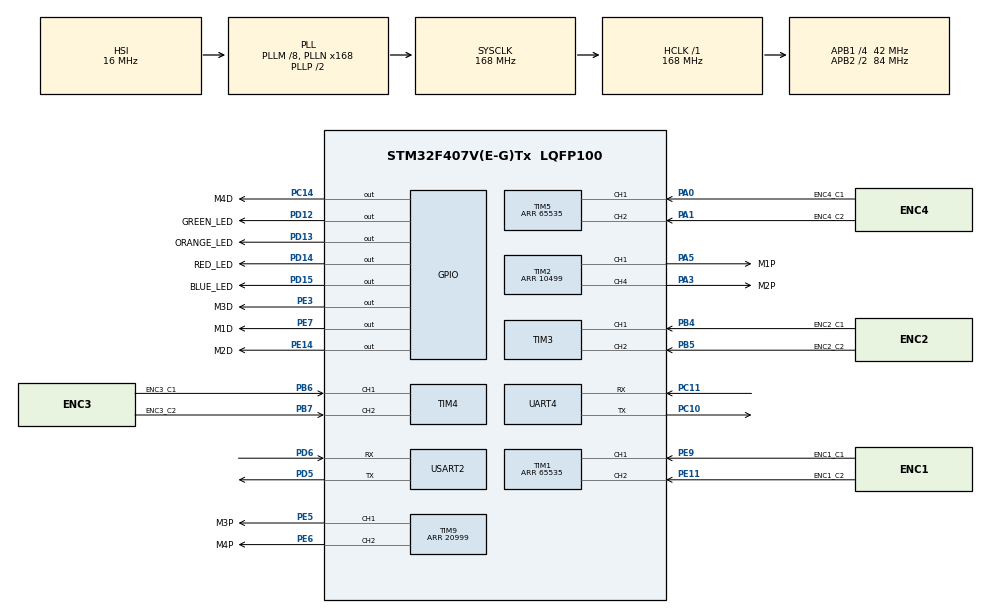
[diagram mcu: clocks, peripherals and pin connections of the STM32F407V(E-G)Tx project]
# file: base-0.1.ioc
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Dma.Request0=USART2_RX
Dma.Request1=UART4_RX
Dma.Request2=UART4_TX
Dma.UART4_RX.1.Direction=DMA_PERIPH_TO_MEMORY
Dma.UART4_RX.1.FIFOMode=DMA_FIFOMODE_DISABLE
Dma.UART4_RX.1.Instance=DMA1_Stream2
Dma.UART4_RX.1.MemDataAlignment=DMA_MDATAALIGN_BYTE
Dma.UART4_RX.1.MemInc=DMA_MINC_ENABLE
Dma.UART4_RX.1.Mode=DMA_NORMAL
Dma.UART4_RX.1.PeriphDataAlignment=DMA_PDATAALIGN_BYTE
Dma.UART4_RX.1.PeriphInc=DMA_PINC_DISABLE
Dma.UART4_RX.1.Priority=DMA_PRIORITY_LOW
Dma.UART4_TX.2.Direction=DMA_MEMORY_TO_PERIPH
Dma.UART4_TX.2.FIFOMode=DMA_FIFOMODE_DISABLE
Dma.UART4_TX.2.Instance=DMA1_Stream4
Dma.UART4_TX.2.MemDataAlignment=DMA_MDATAALIGN_BYTE
Dma.UART4_TX.2.MemInc=DMA_MINC_ENABLE
Dma.UART4_TX.2.Mode=DMA_NORMAL
Dma.UART4_TX.2.PeriphDataAlignment=DMA_PDATAALIGN_BYTE
Dma.UART4_TX.2.PeriphInc=DMA_PINC_DISABLE
Dma.UART4_TX.2.Priority=DMA_PRIORITY_LOW
Dma.USART2_RX.0.Direction=DMA_PERIPH_TO_MEMORY
Dma.USART2_RX.0.FIFOMode=DMA_FIFOMODE_DISABLE
Dma.USART2_RX.0.Instance=DMA1_Stream5
Dma.USART2_RX.0.MemDataAlignment=DMA_MDATAALIGN_BYTE
Dma.USART2_RX.0.MemInc=DMA_MINC_ENABLE
Dma.USART2_RX.0.Mode=DMA_NORMAL
Dma.USART2_RX.0.PeriphDataAlignment=DMA_PDATAALIGN_BYTE
Dma.USART2_RX.0.PeriphInc=DMA_PINC_DISABLE
Dma.USART2_RX.0.Priority=DMA_PRIORITY_MEDIUM
Mcu.Family=STM32F4
Mcu.Name=STM32F407V(E-G)Tx
Mcu.Package=LQFP100
NVIC.DMA1_Stream2_IRQn=true\:0\:0\:false\:false\:true\:false\:true\:true
NVIC.DMA1_Stream4_IRQn=true\:0\:0\:false\:false\:true\:false\:true\:true
NVIC.DMA1_Stream5_IRQn=true\:0\:0\:false\:false\:true\:false\:true\:true
NVIC.PriorityGroup=NVIC_PRIORITYGROUP_0
NVIC.USART2_IRQn=true\:0\:0\:false\:false\:true\:true\:true\:true
PA0-WKUP.GPIO_Label=ENC4_C1
PA0-WKUP.Signal=S_TIM5_CH1
PA1.GPIO_Label=ENC4_C2
PA1.Signal=S_TIM5_CH2
PA13.Mode=Serial_Wire
PA13.Signal=SYS_JTMS-SWDIO
PA14.Mode=Serial_Wire
PA14.Signal=SYS_JTCK-SWCLK
PA3.GPIO_Label=M2P
PA3.Signal=S_TIM2_CH4
PA5.GPIO_Label=M1P
PA5.Signal=S_TIM2_CH1_ETR
PB4.GPIO_Label=ENC2_C1
PB4.Signal=S_TIM3_CH1
PB5.GPIO_Label=ENC2_C2
PB5.Signal=S_TIM3_CH2
PB6.GPIO_Label=ENC3_C1
PB6.Signal=S_TIM4_CH1
PB7.GPIO_Label=ENC3_C2
PB7.Signal=S_TIM4_CH2
PC10.Mode=Asynchronous
PC10.Signal=UART4_TX
PC11.Mode=Asynchronous
PC11.Signal=UART4_RX
PC14-OSC32_IN.GPIO_Label=M4D
PC14-OSC32_IN.Signal=GPIO_Output
PD12.GPIO_Label=GREEN_LED
PD12.Signal=GPIO_Output
PD13.GPIO_Label=ORANGE_LED
PD13.Signal=GPIO_Output
PD14.GPIO_Label=RED_LED
PD14.Signal=GPIO_Output
PD15.GPIO_Label=BLUE_LED
PD15.Signal=GPIO_Output
PD5.Mode=Asynchronous
PD5.Signal=USART2_TX
PD6.Mode=Asynchronous
PD6.Signal=USART2_RX
PE11.GPIO_Label=ENC1_C2
PE11.Signal=S_TIM1_CH2
PE14.GPIO_Label=M2D
PE14.Signal=GPIO_Output
PE3.GPIO_Label=M3D
PE3.Signal=GPIO_Output
PE5.GPIO_Label=M3P
PE5.Signal=S_TIM9_CH1
PE6.GPIO_Label=M4P
PE6.Signal=S_TIM9_CH2
PE7.GPIO_Label=M1D
PE7.Signal=GPIO_Output
PE9.GPIO_Label=ENC1_C1
PE9.Signal=S_TIM1_CH1
PH0-OSC_IN.Mode=HSE-External-Oscillator
PH0-OSC_IN.Signal=RCC_OSC_IN
PH1-OSC_OUT.Mode=HSE-External-Oscillator
PH1-OSC_OUT.Signal=RCC_OSC_OUT
ProjectManager.HeapSize=0x200
ProjectManager.StackSize=0x400
ProjectManager.TargetToolchain=Makefile
RCC.48MHZClocksFreq_Value=48000000
RCC.AHBFreq_Value=168000000
RCC.APB1CLKDivider=RCC_HCLK_DIV4
RCC.APB1Freq_Value=42000000
RCC.APB1TimFreq_Value=84000000
RCC.APB2CLKDivider=RCC_HCLK_DIV2
RCC.APB2Freq_Value=84000000
RCC.APB2TimFreq_Value=168000000
RCC.CortexFreq_Value=168000000
RCC.HCLKFreq_Value=168000000
RCC.HSE_VALUE=8000000
RCC.HSI_VALUE=16000000
RCC.LSE_VALUE=32768
RCC.PLLM=8
RCC.PLLN=168
RCC.PLLQ=7
RCC.SYSCLKFreq_VALUE=168000000
RCC.SYSCLKSource=RCC_SYSCLKSOURCE_PLLCLK
RCC.VCOOutputFreq_Value=336000000
SH.S_TIM1_CH1.0=TIM1_CH1,Encoder_Interface
SH.S_TIM1_CH2.0=TIM1_CH2,Encoder_Interface
SH.S_TIM2_CH1_ETR.0=TIM2_CH1,PWM Generation1 CH1
SH.S_TIM2_CH4.0=TIM2_CH4,PWM Generation4 CH4
SH.S_TIM3_CH1.0=TIM3_CH1,Encoder_Interface
SH.S_TIM3_CH2.0=TIM3_CH2,Encoder_Interface
SH.S_TIM4_CH1.0=TIM4_CH1,Encoder_Interface
SH.S_TIM4_CH2.0=TIM4_CH2,Encoder_Interface
SH.S_TIM5_CH1.0=TIM5_CH1,Encoder_Interface
SH.S_TIM5_CH2.0=TIM5_CH2,Encoder_Interface
SH.S_TIM9_CH1.0=TIM9_CH1,PWM Generation1 CH1
SH.S_TIM9_CH2.0=TIM9_CH2,PWM Generation2 CH2
TIM1.AutoReloadPreload=TIM_AUTORELOAD_PRELOAD_DISABLE
TIM1.EncoderMode=TIM_ENCODERMODE_TI12
TIM1.Period=65535
TIM2.Channel-PWM\ Generation1\ CH1=TIM_CHANNEL_1
TIM2.Channel-PWM\ Generation4\ CH4=TIM_CHANNEL_4
TIM2.Period=10499
TIM3.AutoReloadPreload=TIM_AUTORELOAD_PRELOAD_DISABLE
TIM3.EncoderMode=TIM_ENCODERMODE_TI12
TIM4.AutoReloadPreload=TIM_AUTORELOAD_PRELOAD_DISABLE
TIM4.EncoderMode=TIM_ENCODERMODE_TI12
TIM5.Channel-PWM\ Generation4\ CH4=TIM_CHANNEL_4
TIM5.EncoderMode=TIM_ENCODERMODE_TI12
TIM5.Period=65535
TIM9.AutoReloadPreload=TIM_AUTORELOAD_PRELOAD_DISABLE
TIM9.Channel-PWM\ Generation1\ CH1=TIM_CHANNEL_1
TIM9.Channel-PWM\ Generation2\ CH2=TIM_CHANNEL_2
TIM9.Period=20999
UART4.VirtualMode=Asynchronous
USART2.VirtualMode=VM_ASYNC
board=STM32F407G-DISC1

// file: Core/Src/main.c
/* USER CODE BEGIN Header */
/**
  ******************************************************************************
  * @file           : main.c
  * @brief          : Main program body
  ******************************************************************************
  * @attention
  *
  * Copyright (c) 2023 STMicroelectronics.
  * All rights reserved.
  *
  * This software is licensed under terms that can be found in the LICENSE file
  * in the root directory of this software component.
  * If no LICENSE file comes with this software, it is provided AS-IS.
  *
  ******************************************************************************
  */
/* USER CODE END Header */
#include "main.h"
#include "dma.h"
#include "tim.h"
#include "usart.h"
#include "gpio.h"

/* USER CODE BEGIN Includes */
#include "Robot_main.h"
/* USER CODE END Includes */

void SystemClock_Config(void);

int main(void)
{

  /* MCU Configuration--------------------------------------------------------*/

  /* Reset of all peripherals, Initializes the Flash interface and the Systick. */
  HAL_Init();

  /* Configure the system clock */
  SystemClock_Config();

  /* Initialize all configured peripherals */
  MX_GPIO_Init();
  MX_DMA_Init();
  MX_TIM2_Init();
  MX_TIM9_Init();
  MX_TIM1_Init();
  MX_TIM3_Init();
  MX_TIM4_Init();
  MX_TIM5_Init();
  MX_USART2_UART_Init();
  MX_UART4_Init();

  /* Infinite loop */
  /* USER CODE BEGIN WHILE */
  while (1)
  {
    // Robot_main returns 0 if need to reboot
    int run = Robot_main();

    if (run != 0)
      break;

    /* USER CODE END WHILE */

  }
}

void SystemClock_Config(void)
{
  RCC_OscInitTypeDef RCC_OscInitStruct = {0};
  RCC_ClkInitTypeDef RCC_ClkInitStruct = {0};

  /** Configure the main internal regulator output voltage
  */
  __HAL_RCC_PWR_CLK_ENABLE();
  __HAL_PWR_VOLTAGESCALING_CONFIG(PWR_REGULATOR_VOLTAGE_SCALE1);

  /** Initializes the RCC Oscillators according to the specified parameters
  * in the RCC_OscInitTypeDef structure.
  */
  RCC_OscInitStruct.OscillatorType = RCC_OSCILLATORTYPE_HSI;
  RCC_OscInitStruct.HSIState = RCC_HSI_ON;
  RCC_OscInitStruct.HSICalibrationValue = RCC_HSICALIBRATION_DEFAULT;
  RCC_OscInitStruct.PLL.PLLState = RCC_PLL_ON;
  RCC_OscInitStruct.PLL.PLLSource = RCC_PLLSOURCE_HSI;
  RCC_OscInitStruct.PLL.PLLM = 8;
  RCC_OscInitStruct.PLL.PLLN = 168;
  RCC_OscInitStruct.PLL.PLLP = RCC_PLLP_DIV2;
  RCC_OscInitStruct.PLL.PLLQ = 7;
  if (HAL_RCC_OscConfig(&RCC_OscInitStruct) != HAL_OK)
  {
    Error_Handler();
  }

  /** Initializes the CPU, AHB and APB buses clocks
  */
  RCC_ClkInitStruct.ClockType = RCC_CLOCKTYPE_HCLK|RCC_CLOCKTYPE_SYSCLK
                              |RCC_CLOCKTYPE_PCLK1|RCC_CLOCKTYPE_PCLK2;
  RCC_ClkInitStruct.SYSCLKSource = RCC_SYSCLKSOURCE_PLLCLK;
  RCC_ClkInitStruct.AHBCLKDivider = RCC_SYSCLK_DIV1;
  RCC_ClkInitStruct.APB1CLKDivider = RCC_HCLK_DIV4;
  RCC_ClkInitStruct.APB2CLKDivider = RCC_HCLK_DIV2;

  if (HAL_RCC_ClockConfig(&RCC_ClkInitStruct, FLASH_LATENCY_5) != HAL_OK)
  {
    Error_Handler();
  }
}

void Error_Handler(void)
{
  __disable_irq();
  while (1)
  {
  }
}
